# MKL28T7_CORE0 register map
Vendor: Freescale Semiconductor, Inc.; Series: Kinetis_L; File version: 1.6
CPU: CM0PLUS r0p0, little endian, no MPU, no FPU, VTOR, 2 interrupt priority bits
Registers are 32-bit, read-write, reset 0x0 unless marked. A register's access mark holds for its fields unless they carry their own. Offsets are from the block's base; [hi:lo] are bit positions; {n}, {i} and the like mark numbered series; 'fields as' and 'values as' point back to an identical list.

## TRNG — RNG
Base 0x400A5000
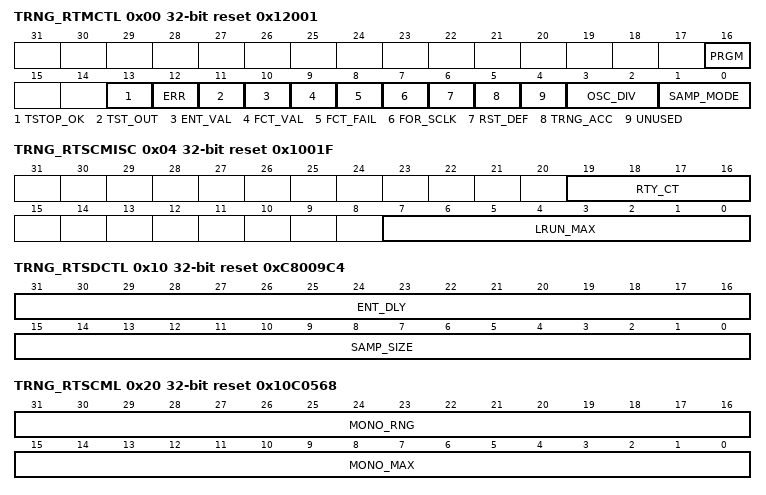
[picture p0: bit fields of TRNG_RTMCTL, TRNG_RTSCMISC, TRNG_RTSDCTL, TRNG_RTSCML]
0x00 TRNG_RTMCTL reset 0x12001 — RNG Miscellaneous Control Register
  [16] PRGM — Programming Mode Select
  [13] TSTOP_OK ro — TRNG_OK_TO_STOP
  [12] ERR — Read: Error status
  [11] TST_OUT ro — Read only: Test point inside ring oscillator.
  [10] ENT_VAL ro — Read only: Entropy Valid
  [9] FCT_VAL ro — Read only: Frequency Count Valid. Indicates that a valid frequency count may be read from true.
  [8] FCT_FAIL ro — Read only: Frequency Count Fail
  [7] FOR_SCLK — Force System Clock
  [6] RST_DEF wo — Reset Defaults
  [5] TRNG_ACC — TRNG Access Mode
  [4] UNUSED — This bit is unused but write-able. Must be left as zero.
  [3:2] OSC_DIV — Oscillator Divide
    0=use ring oscillator with no divide; 1=use ring oscillator divided-by-2; 2=use ring oscillator divided-by-4; 3=use ring oscillator divided-by-8
  [1:0] SAMP_MODE — Sample Mode
    0=use Von Neumann data into both Entropy shifter and Statistical Checker; 1=use raw data into both Entropy shifter and Statistical Checker; 2=use Von Neumann data into Entropy shifter. Use raw data into Statistical Checker
0x04 TRNG_RTSCMISC reset 0x1001F — RNG Statistical Check Miscellaneous Register
  [19:16] RTY_CT — RETRY COUNT
  [7:0] LRUN_MAX — LONG RUN MAX LIMIT
0x08 TRNG_RTPKRRNG reset 0x9A3 — RNG Poker Range Register
  [15:0] PKR_RNG — Poker Range
0x0C TRNG_RTPKRMAX reset 0x6920 (TRNG view) — RNG Poker Maximum Limit Register
  [23:0] PKR_MAX — Poker Maximum Limit
0x0C TRNG_RTPKRSQ ro (TRNG view) — RNG Poker Square Calculation Result Register
  [23:0] PKR_SQ — Poker Square Calculation Result
0x10 TRNG_RTSDCTL reset 0xC8009C4 — RNG Seed Control Register
  [31:16] ENT_DLY — Entropy Delay
  [15:0] SAMP_SIZE — Sample Size
0x14 TRNG_RTSBLIM reset 0x3F (TRNG view) — RNG Sparse Bit Limit Register
  [9:0] SB_LIM — Sparse Bit Limit
0x14 TRNG_RTTOTSAM ro (TRNG view) — RNG Total Samples Register
  [19:0] TOT_SAM — Total Samples
0x18 TRNG_RTFRQMIN reset 0x640 — RNG Frequency Count Minimum Limit Register
  [21:0] FRQ_MIN — Frequency Count Minimum Limit
0x1C TRNG_RTFRQCNT ro (TRNG view) — RNG Frequency Count Register
  [21:0] FRQ_CT — Frequency Count
0x1C TRNG_RTFRQMAX reset 0x6400 (TRNG view) — RNG Frequency Count Maximum Limit Register
  [21:0] FRQ_MAX — Frequency Counter Maximum Limit
0x20 TRNG_RTSCMC ro (TRNG view) — RNG Statistical Check Monobit Count Register
  [15:0] MONO_CT — Monobit Count
0x20 TRNG_RTSCML reset 0x10C0568 (TRNG view) — RNG Statistical Check Monobit Limit Register
  [31:16] MONO_RNG — Monobit Range
  [15:0] MONO_MAX — Monobit Maximum Limit
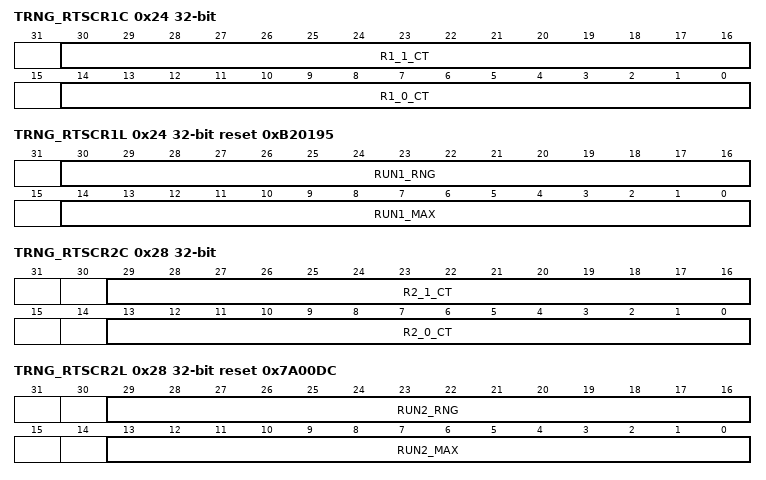
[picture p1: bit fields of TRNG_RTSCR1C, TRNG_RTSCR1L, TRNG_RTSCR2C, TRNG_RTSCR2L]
0x24 TRNG_RTSCR1C ro (TRNG view) — RNG Statistical Check Run Length 1 Count Register
  [30:16] R1_1_CT — Runs of One, Length 1 Count
  [14:0] R1_0_CT — Runs of Zero, Length 1 Count
0x24 TRNG_RTSCR1L reset 0xB20195 (TRNG view) — RNG Statistical Check Run Length 1 Limit Register
  [30:16] RUN1_RNG — Run Length 1 Range
  [14:0] RUN1_MAX — Run Length 1 Maximum Limit
0x28 TRNG_RTSCR2C ro (TRNG view) — RNG Statistical Check Run Length 2 Count Register
  [29:16] R2_1_CT — Runs of One, Length 2 Count
  [13:0] R2_0_CT — Runs of Zero, Length 2 Count
0x28 TRNG_RTSCR2L reset 0x7A00DC (TRNG view) — RNG Statistical Check Run Length 2 Limit Register
  [29:16] RUN2_RNG — Run Length 2 Range
  [13:0] RUN2_MAX — Run Length 2 Maximum Limit
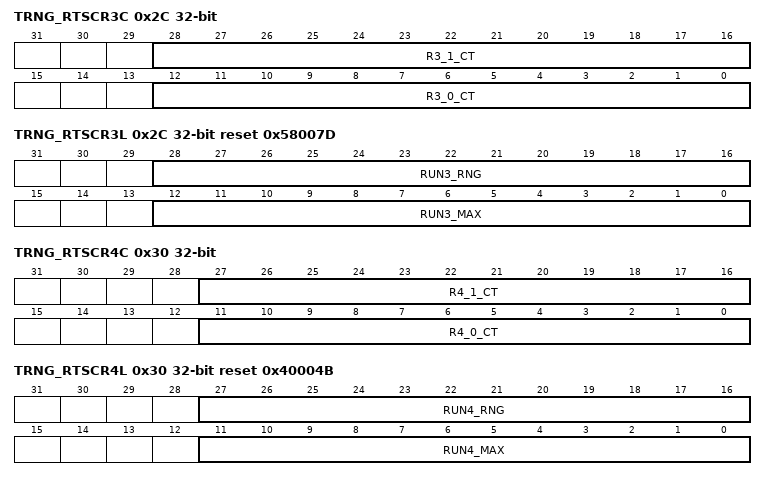
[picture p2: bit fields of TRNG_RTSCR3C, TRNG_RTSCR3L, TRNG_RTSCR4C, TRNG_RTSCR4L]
0x2C TRNG_RTSCR3C ro (TRNG view) — RNG Statistical Check Run Length 3 Count Register
  [28:16] R3_1_CT — Runs of Ones, Length 3 Count
  [12:0] R3_0_CT — Runs of Zeroes, Length 3 Count
0x2C TRNG_RTSCR3L reset 0x58007D (TRNG view) — RNG Statistical Check Run Length 3 Limit Register
  [28:16] RUN3_RNG — Run Length 3 Range
  [12:0] RUN3_MAX — Run Length 3 Maximum Limit
0x30 TRNG_RTSCR4C ro (TRNG view) — RNG Statistical Check Run Length 4 Count Register
  [27:16] R4_1_CT — Runs of One, Length 4 Count
  [11:0] R4_0_CT — Runs of Zero, Length 4 Count
0x30 TRNG_RTSCR4L reset 0x40004B (TRNG view) — RNG Statistical Check Run Length 4 Limit Register
  [27:16] RUN4_RNG — Run Length 4 Range
  [11:0] RUN4_MAX — Run Length 4 Maximum Limit
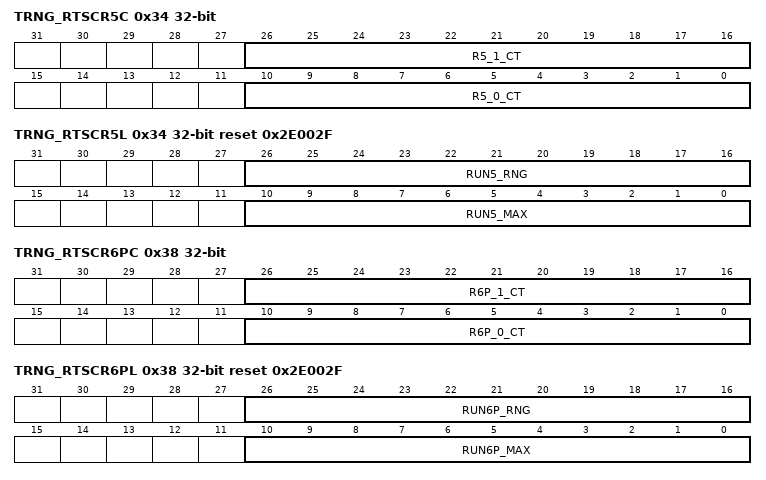
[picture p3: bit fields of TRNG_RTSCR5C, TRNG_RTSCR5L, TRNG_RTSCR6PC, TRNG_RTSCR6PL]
0x34 TRNG_RTSCR5C ro (TRNG view) — RNG Statistical Check Run Length 5 Count Register
  [26:16] R5_1_CT — Runs of One, Length 5 Count
  [10:0] R5_0_CT — Runs of Zero, Length 5 Count
0x34 TRNG_RTSCR5L reset 0x2E002F (TRNG view) — RNG Statistical Check Run Length 5 Limit Register
  [26:16] RUN5_RNG — Run Length 5 Range
  [10:0] RUN5_MAX — Run Length 5 Maximum Limit
0x38 TRNG_RTSCR6PC ro (TRNG view) — RNG Statistical Check Run Length 6+ Count Register
  [26:16] R6P_1_CT — Runs of One, Length 6+ Count
  [10:0] R6P_0_CT — Runs of Zero, Length 6+ Count
0x38 TRNG_RTSCR6PL reset 0x2E002F (TRNG view) — RNG Statistical Check Run Length 6+ Limit Register
  [26:16] RUN6P_RNG — Run Length 6+ Range
  [10:0] RUN6P_MAX — Run Length 6+ Maximum Limit
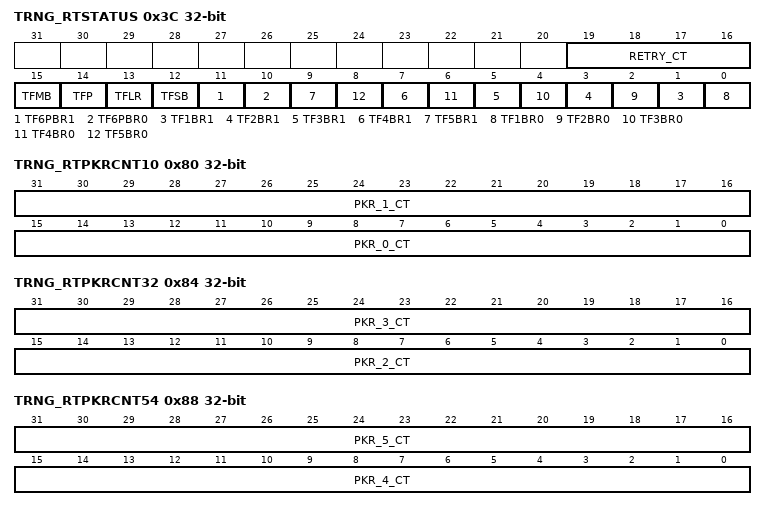
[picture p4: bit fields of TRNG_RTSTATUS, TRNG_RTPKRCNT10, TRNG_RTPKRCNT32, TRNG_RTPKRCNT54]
0x3C TRNG_RTSTATUS ro — RNG Status Register
  [19:16] RETRY_CT — RETRY COUNT
  [15] TFMB — Test Fail, Mono Bit. If TFMB=1, the Mono Bit Test has failed.
  [14] TFP — Test Fail, Poker. If TFP=1, the Poker Test has failed.
  [13] TFLR — Test Fail, Long Run. If TFLR=1, the Long Run Test has failed.
  [12] TFSB — Test Fail, Sparse Bit. If TFSB=1, the Sparse Bit Test has failed.
  [11] TF6PBR1 — Test Fail, 6 Plus Bit Run, Sampling 1s
  [10] TF6PBR0 — Test Fail, 6 Plus Bit Run, Sampling 0s
  [2n-1] TF{n}BR1 (n=1..5) — Test Fail, {n}-Bit Run, Sampling 1s. If TF{n}BR1=1, the {n}-Bit Run, Sampling 1s Test has failed.
  [2n-2] TF{n}BR0 (n=1..5) — Test Fail, {n}-Bit Run, Sampling 0s. If TF{n}BR0=1, the {n}-Bit Run, Sampling 0s Test has failed.
{0x40+4i} TRNG_RTENT{i} ro (i=0..15) — RNG TRNG Entropy Read Register
  [31:0] ENT — Entropy Value
0x80 TRNG_RTPKRCNT10 ro — RNG Statistical Check Poker Count 1 and 0 Register
  [31:16] PKR_1_CT — Poker 1h Count
  [15:0] PKR_0_CT — Poker 0h Count
0x84 TRNG_RTPKRCNT32 ro — RNG Statistical Check Poker Count 3 and 2 Register
  [31:16] PKR_3_CT — Poker 3h Count
  [15:0] PKR_2_CT — Poker 2h Count
0x88 TRNG_RTPKRCNT54 ro — RNG Statistical Check Poker Count 5 and 4 Register
  [31:16] PKR_5_CT — Poker 5h Count
  [15:0] PKR_4_CT — Poker 4h Count
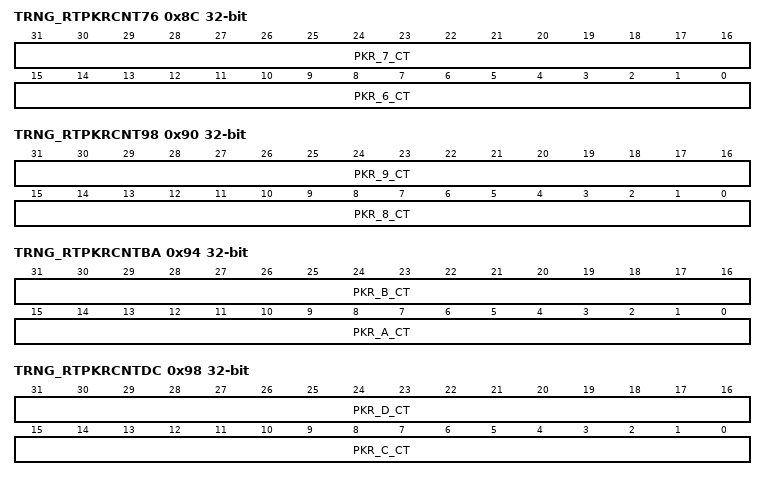
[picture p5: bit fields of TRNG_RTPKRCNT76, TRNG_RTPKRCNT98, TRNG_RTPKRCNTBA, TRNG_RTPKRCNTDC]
0x8C TRNG_RTPKRCNT76 ro — RNG Statistical Check Poker Count 7 and 6 Register
  [31:16] PKR_7_CT — Poker 7h Count
  [15:0] PKR_6_CT — Poker 6h Count
0x90 TRNG_RTPKRCNT98 ro — RNG Statistical Check Poker Count 9 and 8 Register
  [31:16] PKR_9_CT — Poker 9h Count
  [15:0] PKR_8_CT — Poker 8h Count
0x94 TRNG_RTPKRCNTBA ro — RNG Statistical Check Poker Count B and A Register
  [31:16] PKR_B_CT — Poker Bh Count
  [15:0] PKR_A_CT — Poker Ah Count
0x98 TRNG_RTPKRCNTDC ro — RNG Statistical Check Poker Count D and C Register
  [31:16] PKR_D_CT — Poker Dh Count
  [15:0] PKR_C_CT — Poker Ch Count
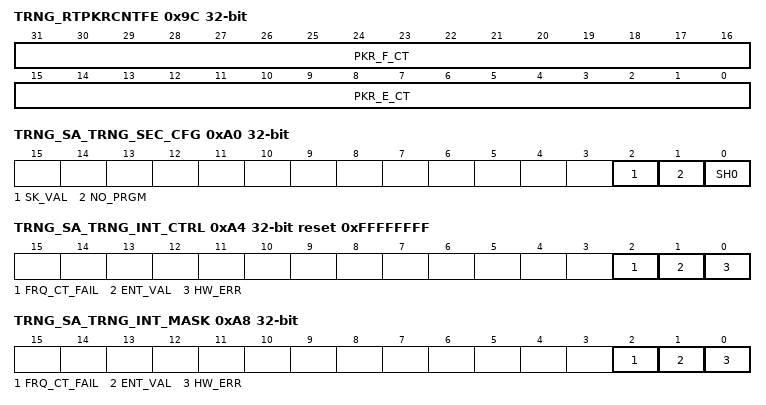
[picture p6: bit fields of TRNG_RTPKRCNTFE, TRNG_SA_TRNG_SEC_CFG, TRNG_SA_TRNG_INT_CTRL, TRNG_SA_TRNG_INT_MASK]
0x9C TRNG_RTPKRCNTFE ro — RNG Statistical Check Poker Count F and E Register
  [31:16] PKR_F_CT — Poker Fh Count
  [15:0] PKR_E_CT — Poker Eh Count
0xA0 TRNG_SA_TRNG_SEC_CFG — RNG Security Configuration Register
  [2] SK_VAL — Reserved. DRNG-specific, not applicable to this version.
    0=See DRNG version; 1=See DRNG version
  [1] NO_PRGM — If set the TRNG registers cannot be programmed
    0=Programability of registers controlled only by the RNG Miscellaneous Control Register's access mode bit; 1=Overides RNG Miscellaneous Control Register access mode and prevents TRNG register programming
  [0] SH0 — Reserved. DRNG specific, not applicable to this version.
    0=See DRNG version; 1=See DRNG version
0xA4 TRNG_SA_TRNG_INT_CTRL reset 0xFFFFFFFF — RNG Interrupt Control Register
  [2] FRQ_CT_FAIL — Same behavior as bit 0 above.
    0=Same behavior as bit 0 above; 1=Same behavior as bit 0 above
  [1] ENT_VAL — Same behavior as bit 0 above.
    values as FRQ_CT_FAIL
  [0] HW_ERR — Bit position that can be cleared if corresponding bit of true has been asserted.
    0=Corresponding bit of true cleared; 1=Corresponding bit of true active
0xA8 TRNG_SA_TRNG_INT_MASK — RNG Mask Register
  [2] FRQ_CT_FAIL — Same behavior as bit 0 above.
    values as TRNG_SA_TRNG_INT_CTRL.FRQ_CT_FAIL
  [1] ENT_VAL — Same behavior as bit 0 above.
    values as TRNG_SA_TRNG_INT_CTRL.FRQ_CT_FAIL
  [0] HW_ERR — Bit position that can be cleared if corresponding bit of true has been asserted.
    0=Corresponding interrupt of true is masked; 1=Corresponding bit of true is active
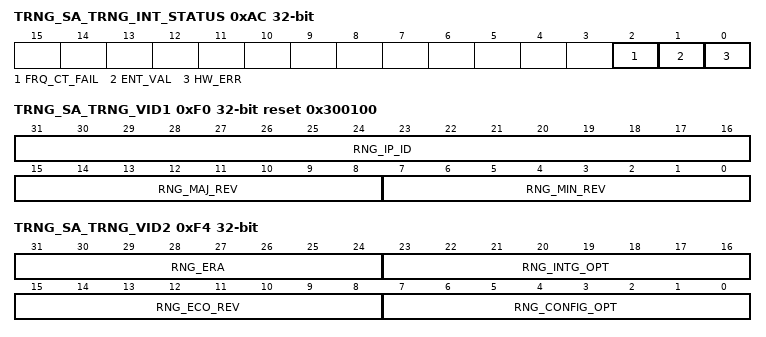
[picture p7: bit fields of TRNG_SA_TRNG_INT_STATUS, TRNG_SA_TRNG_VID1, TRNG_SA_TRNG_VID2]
0xAC TRNG_SA_TRNG_INT_STATUS — RNG Interrupt Status Register
  [2] FRQ_CT_FAIL — Read only: Frequency Count Fail
    0=No hardware nor self test frequency errors; 1=The frequency counter has detected a failure
  [1] ENT_VAL ro — Read only: Entropy Valid
    0=Busy generation entropy. Any value read is invalid.; 1=TRNG can be stopped and entropy is valid if read
  [0] HW_ERR ro — Read: Error status
    0=no error; 1=error detected
0xF0 TRNG_SA_TRNG_VID1 ro reset 0x300100 — RNG Version ID Register (MS)
  [31:16] RNG_IP_ID — Shows the Freescale IP ID.
  [15:8] RNG_MAJ_REV — Shows the Freescale IP's Major revision of the TRNG.
    1=Major revision number for TRNG
  [7:0] RNG_MIN_REV — Shows the Freescale IP's Minor revision of the TRNG.
    0=Minor revision number for TRNG
0xF4 TRNG_SA_TRNG_VID2 ro — RNG Version ID Register (LS)
  [31:24] RNG_ERA — Shows the Freescale compile options for the TRNG.
    0=COMPILE_OPT for TRNG
  [23:16] RNG_INTG_OPT — Shows the Freescale integration options for the TRNG.
    0=INTG_OPT for TRNG
  [15:8] RNG_ECO_REV — Shows the Freescale IP's ECO revision of the TRNG.
    0=TRNG_ECO_REV for TRNG
  [7:0] RNG_CONFIG_OPT — Shows the Freescale IP's Configuaration options for the TRNG.
    0=TRNG_CONFIG_OPT for TRNG
